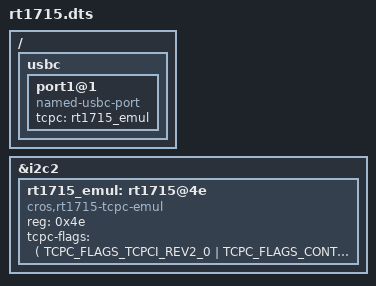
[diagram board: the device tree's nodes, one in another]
/* Copyright 2024 The ChromiumOS Authors
 * Use of this source code is governed by a BSD-style license that can be
 * found in the LICENSE file.
 */

#include <dt-bindings/usb_pd_tcpm.h>

/ {
	usbc {
		port1@1 {
			compatible = "named-usbc-port";
			tcpc = <&rt1715_emul>;
		};
	};
};

&i2c2 {
	status="okay";

	rt1715_emul: rt1715@4e {
		compatible = "cros,rt1715-tcpc-emul", "richtek,rt1715-tcpc";
		status = "okay";
		reg = <0x4e>;
		tcpc-flags = <(
			TCPC_FLAGS_TCPCI_REV2_0 |
			TCPC_FLAGS_CONTROL_VCONN |
			TCPC_FLAGS_TCPCI_REV2_0_NO_VSAFE0V)>;
	};
};
